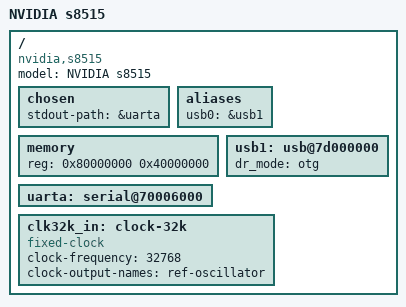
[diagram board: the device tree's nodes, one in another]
// SPDX-License-Identifier: GPL-2.0
/dts-v1/;

#include <dt-bindings/input/input.h>
#include "tegra114.dtsi"

/ {
	model = "NVIDIA s8515";
	compatible = "nvidia,s8515", "nvidia,tegra114";

	chosen {
		stdout-path = &uarta;
	};

	aliases {
		usb0 = &usb1;
	};

	memory {
		device_type = "memory";
		reg = <0x80000000 0x40000000>;
	};

	uarta: serial@70006000 {
		status = "okay";
	};

	usb1: usb@7d000000 {
		status = "okay";
		dr_mode = "otg";
	};

	clk32k_in: clock-32k {
		compatible = "fixed-clock";
		#clock-cells = <0>;
		clock-frequency = <32768>;
		clock-output-names = "ref-oscillator";
	};
};
